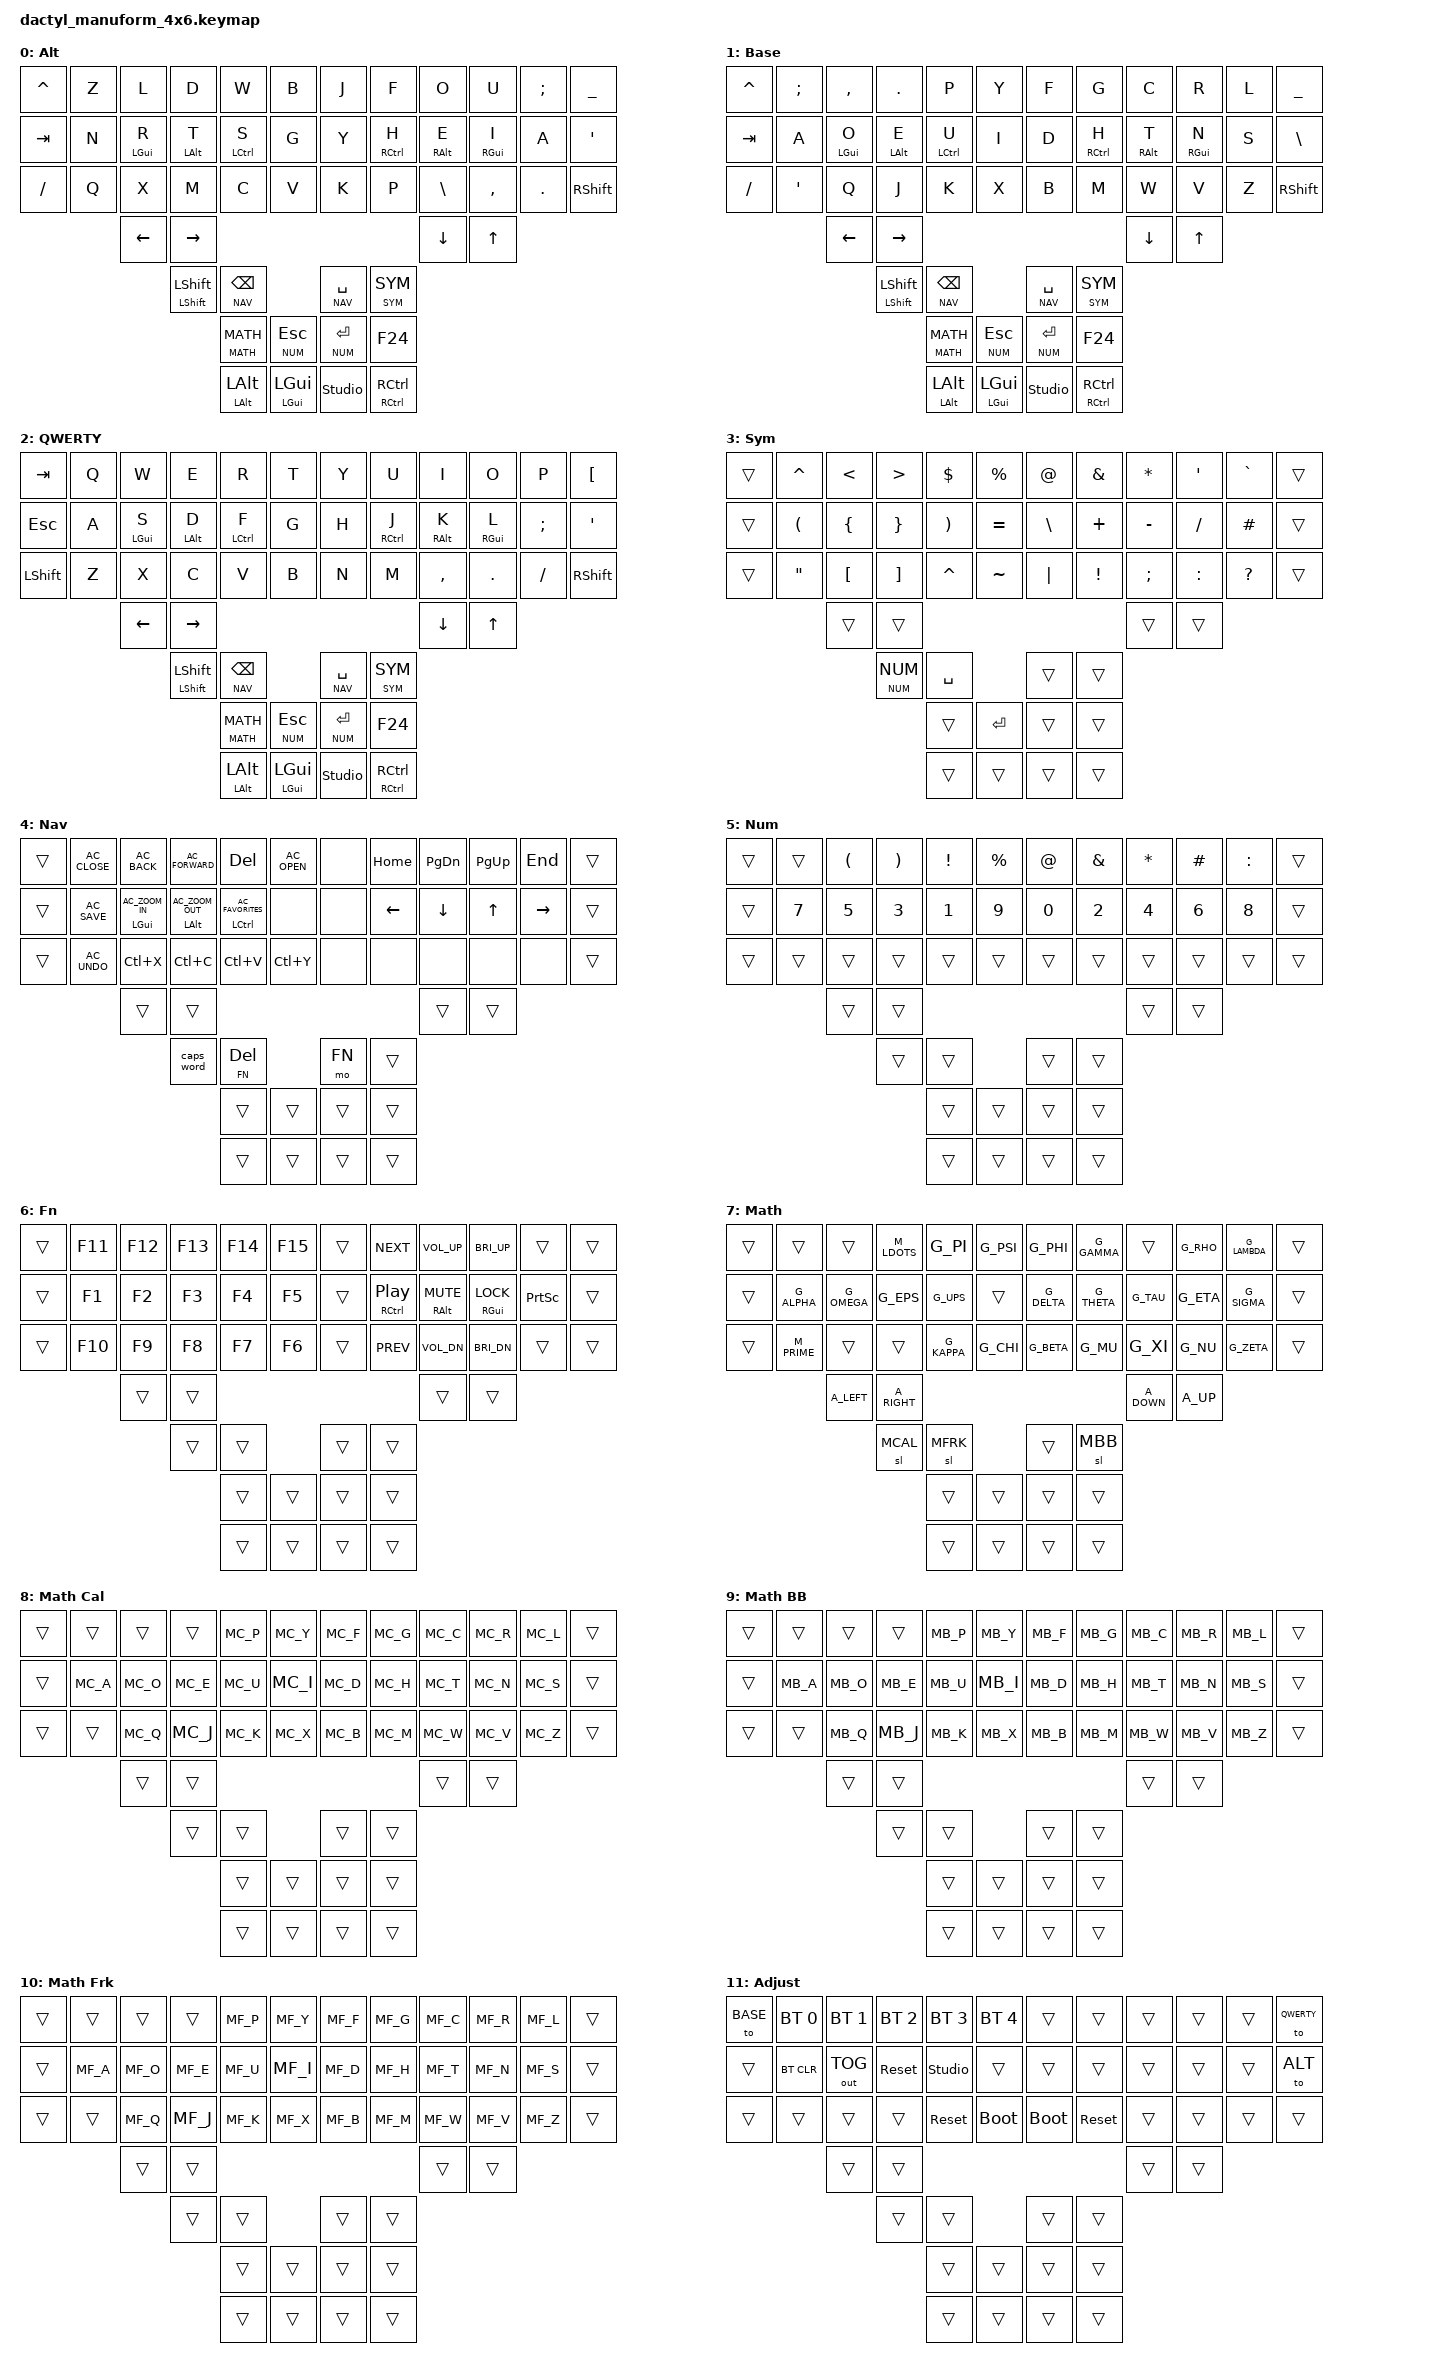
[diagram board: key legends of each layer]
#include <behaviors.dtsi>
#include <dt-bindings/zmk/keys.h>
#include <dt-bindings/zmk/bt.h>
#include <dt-bindings/zmk/outputs.h>
#include <behaviors/unicode.dtsi>   // urob/zmk-unicode: &uc for Unicode input
#include "math_symbols.h"           // G_* / M_* / S_* / A_* / R_* / B_* macros
#include "math_calligraphic.h"      // MC_A .. MC_Z (𝒜 .. 𝒵)
#include "math_doublestruck.h"      // MB_A .. MB_Z (𝔸 .. ℤ)
#include "math_fraktur.h"           // MF_A .. MF_Z (𝔞 .. ℨ)

// ALT-default keymap (Option B: firmware sends character names directly,
// host OS stays on plain US QWERTY when using this keyboard).
//
// LAYER ORDER IS LOAD-BEARING. Index comes from block-order in keymap{}, and
// the highest active index wins at any position. So the three ALPHABET layers
// must sit at the BOTTOM (0-2): an alphabet is fully opaque across all 52
// positions, so anything stacked above it would be masked. Feature layers go
// above them, ADJUST last of all.
//
//   0 ALT    — DEFAULT alphabet, from cyanophage.github.io/playground.
//              HRMs on ring/middle/index home row (r/t/s left, h/e/i right).
//   1 BASE   — Dvorak-Programmer alphabet. Reached via &to BASE on ADJUST.
//   2 QWERTY — standard QWERTY alphabet. Reached via &to QWERTY on ADJUST.
//   3 SYM    — symbols on top row (Programmer Dvorak style), numbers on row 1
//   4 NAV    — arrows on right home row, home/pgdn/pgup/end directly above,
//              both on index/middle/ring/pinky. DEL on left index row 0.
//   5 NUM    — numpad / number entry. Entered by holding L or R mid-inner
//              thumb (which tap to ESC or ENTER respectively).
//   6 FN     — function / media keys. Chained from NAV: while NAV is held,
//              L top-inner (BSPC pos) taps to DEL / holds to FN;
//              R top-inner (SPACE pos) is momentary FN. Row 1 right carries
//              &hp mod-taps because entering FN pins both thumbs.
//   7 MATH   — Unicode math/Greek symbols via urob/zmk-unicode. Tap-sticky
//              MATH (F23 / L mid-outer) then tap a letter → Greek symbol.
//              Mimics cdlatex ;a → α flow. Unshifted / shifted (via
//              &uc CP1 CP2) matches cdlatex first two symbols per key.
//              Requires IBus-capable Linux input method (UC_MODE_LINUX).
//              Switchable at runtime via &uc UC_SET_*.
//              NOTE: these positions were laid out against the Dvorak BASE
//              alphabet, so with ALT as default the letter mnemonic no
//              longer lines up (α sits on ALT's `n`, etc.). Functional but
//              needs remapping to ALT positions to restore the mnemonic.
//   8 MCAL   — Mathematical Script (\mathcal): 𝒜 .. 𝒵. Access: from MATH,
//              tap L top-outer thumb — arms one-shot MCAL for next letter.
//   9 MBB    — Double-Struck (\mathbb): 𝔸 .. ℤ. Access: from MATH, R top-outer.
//  10 MFRK   — Fraktur (\mathfrak): 𝔞/𝔄 .. 𝔷/ℨ. Access: from MATH, L top-inner.
//              Includes lowercase (Lie algebras) on tap; uppercase on shift.
//              (MCAL/MBB/MFRK inherit MATH's Dvorak-alignment caveat.)
//  11 ADJUST — BT profiles + output toggle + layout switch + &studio_unlock.
//              (tri-layer: SYM+NAV, or R bot-inner thumb via ADJ). ADJUST
//              top-left = &to BASE, top-right = &to QWERTY, row 1 right
//              = &to ALT. Highest index so it wins over everything.
//
// The matrix transform (see the shield .dtsi) has been reordered so bindings
// below are written in PHYSICAL rather than matrix-scan order. Each layer
// has 7 visual lines:
//
//   Rows 0-2   alphabet: 6 keys per half (row-major).
//   ext line   the two per half on the thumb-row wiring that sit under
//              middle/ring finger, NOT on the thumb pod. Placed far apart
//              to reflect that they're on opposite halves under fingers.
//   top thumb  the 2 easy sweep-friendly keys per half (top of thumb pod).
//   mid thumb  the 2 middle keys per half — inner one is sweep-friendly.
//   bot thumb  the 2 further-reach keys per half.
//
// Left thumb pod physical shape (right is mirrored):
//   [top1  top2]           <- RC(3,4) RC(3,5)
//       [mid1 mid2]        <- RC(4,4) RC(4,5)
//       [bot1 bot2]        <- RC(4,2) RC(4,3)

// missing: CARET
// missing: backtick

// These MUST match the block order inside keymap{} — ZMK assigns the index
// from block position, not from these names. Alphabets occupy 0-2 so that
// every feature layer outranks them; see the layer-order note above.
#define ALT    0   // default layer
#define BASE   1
#define QWERTY 2
#define SYM    3
#define NAV    4
#define NUM    5
#define FN     6
#define MATH   7
#define MCAL   8
#define MBB    9
#define MFRK   10
#define ADJUST 11   // Highest index so ADJUST wins over everything when tri-layer fires

// Position groups in the physical-order transform (see .dtsi):
//   alphabet:  0..5  L row 0     6..11 R row 0
//              12..17 L row 1    18..23 R row 1
//              24..29 L row 2    30..35 R row 2
//   thumb region (rows 3-4 in matrix):
//              36 37  ext L (ring, middle)     38 39  ext R (middle, ring)
//              40 41  top L thumb              42 43  top R thumb
//              44 45  mid L thumb              46 47  mid R thumb
//              48 49  bot L thumb              50 51  bot R thumb
#define KEYS_L    0  1  2  3  4  5 12 13 14 15 16 17 24 25 26 27 28 29
#define KEYS_R    6  7  8  9 10 11 18 19 20 21 22 23 30 31 32 33 34 35
#define THUMBS   36 37 38 39 40 41 42 43 44 45 46 47 48 49 50 51

// NAV layer aliases — short names so bindings fit in the 12-char cell width.
//
// Editor shortcuts (LC(*)):
#define X_UNDO   &kp LC(Z)
#define X_CUT    &kp LC(X)
#define X_COPY   &kp LC(C)
#define X_PASTE  &kp LC(V)
#define X_REDO   &kp LC(Y)

// R bot inner thumb. NOT ADJUST-entry — ZMK's conditional_layers
// deactivates its then-layer whenever if-layers aren't all active,
// which fights any direct &mo/&to ADJUST from here. ADJUST is entered
// via the SYM+NAV tri-layer instead. This slot is &studio_unlock so
// Studio can be unlocked without first entering ADJUST.
#define ADJ      &studio_unlock

// Sticky-hybrid modifier fills for dactyl bot thumbs — tap = one-shot mod,
// hold = held mod. Enables same-hand mod combos that HRM's positional
// constraint blocks (e.g. Ctrl+D on left hand via RCTL held on right thumb).
#define SALT     &sh LALT LALT
#define SGUI     &sh LGUI LGUI
#define SCTL     &sh RCTL RCTL

// MATH layer entry — sticky-hybrid on F23. Tap = one-shot MATH (mimics
// cdlatex ;letter flow); hold = momentary MATH.
#define MTH      &slh MATH MATH

// Default Unicode input system — Linux IBus. Switch at runtime via
// bindings like &uc UC_SET_MACOS or &uc UC_SET_WIN_COMPOSE if needed.
&uc {
    default-mode = <UC_MODE_LINUX>;
};

/ {
    conditional_layers {
        compatible = "zmk,conditional-layers";
        tri_layer {
            if-layers = <SYM NAV>;
            then-layer = <ADJUST>;
        };
    };

    behaviors {
        // Tap-preferred hold-tap for home-row mods. Tap always wins unless
        // held past tapping-term-ms with an interrupting keypress at an
        // allowed (opposite-hand or thumb) position.
        //   require-prior-idle-ms: suppress hold if any key was pressed in
        //                          the last 125ms — kills typing-burst misfires.
        //   quick-tap-ms: tap-then-hold within 175ms auto-repeats the tap
        //                 keycode (useful for hjkl in vim).
        // Split into left/right variants so each side allows only the
        // opposite hand (+ thumbs) as valid interrupters.
        tpl: tap_preferred_left {
            compatible = "zmk,behavior-hold-tap";
            display-name = "HRM (L)";
            #binding-cells = <2>;
            flavor = "tap-preferred";
            tapping-term-ms = <200>;
            require-prior-idle-ms = <125>;
            quick-tap-ms = <175>;
            hold-trigger-key-positions = <KEYS_R THUMBS>;
            bindings = <&kp>, <&kp>;
        };

        tpr: tap_preferred_right {
            compatible = "zmk,behavior-hold-tap";
            display-name = "HRM (R)";
            #binding-cells = <2>;
            flavor = "tap-preferred";
            tapping-term-ms = <200>;
            require-prior-idle-ms = <125>;
            quick-tap-ms = <175>;
            hold-trigger-key-positions = <KEYS_L THUMBS>;
            bindings = <&kp>, <&kp>;
        };

        // Sticky-hybrid modifier. Tap = one-shot mod (next key is modified,
        // then the mod goes away). Hold = normal held mod. Hold-preferred
        // so fast Shift+letter rollovers register as held shift.
        //   Usage: &sh LSHFT LSHFT
        sh: sticky_hold_mod {
            compatible = "zmk,behavior-hold-tap";
            display-name = "Sticky/Hold";
            #binding-cells = <2>;
            flavor = "hold-preferred";
            tapping-term-ms = <200>;
            quick-tap-ms = <175>;
            bindings = <&kp>, <&sk>;
        };

        // Sticky-hybrid layer. Tap = one-shot layer (next key comes from
        // that layer, then base returns). Hold = momentary layer.
        //   Usage: &slh SYM SYM
        slh: sticky_hold_layer {
            compatible = "zmk,behavior-hold-tap";
            display-name = "Sticky Layer";
            #binding-cells = <2>;
            flavor = "hold-preferred";
            tapping-term-ms = <200>;
            bindings = <&mo>, <&sl>;
        };

        // Hold-preferred layer-tap: hold = layer, tap = key. Fires layer on
        // any interrupt OR after tapping-term. Use for thumb keys where the
        // tap is used deliberately (not in fast typing bursts) — e.g. BSPC.
        //   quick-tap-ms: tap-then-hold within 175ms auto-repeats the tap
        //                 keycode (e.g., tap BSPC, then tap-and-hold to
        //                 auto-repeat backspace).
        //   Usage: &lh NAV BSPC
        lh: layer_hold_preferred {
            compatible = "zmk,behavior-hold-tap";
            display-name = "Layer/Tap (H)";
            #binding-cells = <2>;
            flavor = "hold-preferred";
            tapping-term-ms = <200>;
            quick-tap-ms = <175>;
            bindings = <&mo>, <&kp>;
        };

        // Tap-preferred layer-tap: hold = layer, tap = key. Interrupts do
        // NOT trigger hold — only holding past tapping-term does. Safer for
        // fast-typed keys like SPACE.
        //   Usage: &ltp NAV SPACE
        ltp: layer_tap_preferred {
            compatible = "zmk,behavior-hold-tap";
            display-name = "Layer/Tap (T)";
            #binding-cells = <2>;
            flavor = "tap-preferred";
            tapping-term-ms = <300>;
            require-prior-idle-ms = <125>;
            bindings = <&mo>, <&kp>;
        };

        // Hold-preferred mod-tap for the NAV-layer home-row HRMs. Any
        // interrupting keypress triggers the mod immediately (so mod+arrow
        // combos work without waiting for tapping-term). Quick tap alone
        // fires the tap keycode.
        //   Usage: &hp LGUI C_AC_ZOOM_IN
        hp: hp_hold_preferred_mod {
            compatible = "zmk,behavior-hold-tap";
            display-name = "Mod/Tap";
            #binding-cells = <2>;
            flavor = "hold-preferred";
            tapping-term-ms = <150>;
            bindings = <&kp>, <&kp>;
        };
    };

    keymap {
        compatible = "zmk,keymap";

        // DEFAULT alphabet layout — from cyanophage.github.io/playground
        //   layout=zldwbjfou;\nrtsgyheia'qxmcvkp/,.-^
        // Cols 1-10 are the layout's 3x10 alpha grid; col 0 and col 11 are
        // dactyl-only pinky-outer overrides matching BASE's LaTeX-friendly
        // choices (CARET/TAB/FSLH on left; UNDER/SQT/RSHFT on right).
        // Must be layer 0 and must stay fully opaque (no &trans) — it is the
        // bottom of the stack, so a &trans here resolves to nothing.
        alt_layer {
            display-name = "Alt";
            bindings = <
&kp CARET  &kp Z       &kp L       &kp D       &kp W       &kp B           &kp J       &kp F       &kp O       &kp U       &kp SEMI    &kp UNDER
&kp TAB    &kp N       &tpl LGUI R &tpl LALT T &tpl LCTL S &kp G           &kp Y       &tpr RCTL H &tpr RALT E &tpr RGUI I &kp A       &kp SQT
&kp FSLH   &kp Q       &kp X       &kp M       &kp C       &kp V           &kp K       &kp P       &kp BSLH    &kp COMMA   &kp DOT     &kp RSHFT

                       &kp LEFT    &kp RIGHT                                                       &kp DOWN    &kp UP

                                   &sh LSHFT LSHFT &lh NAV BSPC            &ltp NAV SPACE   &slh SYM SYM
                                               MTH         &lh NUM ESC     &lh NUM RET &kp F24
                                               SALT        SGUI            ADJ         SCTL
            >;
        };

        base_layer {
            display-name = "Base";
            bindings = <
&kp CARET  &kp SEMI    &kp COMMA   &kp DOT     &kp P       &kp Y           &kp F       &kp G       &kp C       &kp R       &kp L       &kp UNDER
&kp TAB    &kp A       &tpl LGUI O &tpl LALT E &tpl LCTL U &kp I           &kp D       &tpr RCTL H &tpr RALT T &tpr RGUI N &kp S       &kp BSLH
&kp FSLH  &kp SQT     &kp Q       &kp J       &kp K       &kp X           &kp B       &kp M       &kp W       &kp V       &kp Z       &kp RSHFT

                       &kp LEFT    &kp RIGHT                                                       &kp DOWN    &kp UP

                                   &sh LSHFT LSHFT &lh NAV BSPC            &ltp NAV SPACE   &slh SYM SYM
                                               MTH         &lh NUM ESC     &lh NUM RET &kp F24
                                               SALT        SGUI            ADJ         SCTL
            >;
        };

        // Standard QWERTY. Thumb/extras mirror base so tri-layer to ADJUST still
        // works (hold SYM+NAV, then top-left of ADJUST returns to BASE).
        qwerty_layer {
            display-name = "QWERTY";
            bindings = <
&kp TAB    &kp Q       &kp W       &kp E       &kp R       &kp T           &kp Y       &kp U       &kp I       &kp O       &kp P       &kp LBKT
&kp ESC    &kp A       &tpl LGUI S &tpl LALT D &tpl LCTL F &kp G           &kp H       &tpr RCTL J &tpr RALT K &tpr RGUI L &kp SEMI    &kp SQT
&kp LSHFT  &kp Z       &kp X       &kp C       &kp V       &kp B           &kp N       &kp M       &kp COMMA   &kp DOT     &kp FSLH    &kp RSHFT

                       &kp LEFT    &kp RIGHT                                                       &kp DOWN    &kp UP

                                   &sh LSHFT LSHFT &lh NAV BSPC        &ltp NAV SPACE   &slh SYM SYM
                                               MTH         &lh NUM ESC     &lh NUM RET &kp F24
                                               SALT        SGUI            ADJ         SCTL
            >;
        };

        sym_layer {
            display-name = "Sym";
            bindings = <
&trans   &kp CARET   &kp LT      &kp GT      &kp DLLR    &kp PRCNT       &kp AT      &kp AMPS    &kp STAR    &kp SQT     &kp GRAVE   &trans
&trans   &kp LPAR    &kp LBRC    &kp RBRC    &kp RPAR    &kp EQUAL       &kp BSLH    &kp PLUS    &kp MINUS   &kp FSLH    &kp HASH    &trans      
&trans   &kp DQT     &kp LBKT    &kp RBKT    &kp CARET   &kp TILDE       &kp PIPE    &kp EXCL    &kp SEMI    &kp COLON   &kp QMARK   &trans

                       &trans      &trans                                                          &trans      &trans

                                   &slh NUM NUM    &kp SPACE           &trans          &trans
                                               &trans      &kp ENTER       &trans      &trans
                                               &trans      &trans          &trans      &trans
            >;
        };

        // VIM_NAV layer, adapted from Selenium's HRM vim variant:
        //   left hand  = editor / app-control shortcuts. Row 0: browser back/
        //                fwd + ctl-w. Row 1: SAVE + ZOOM_IN/OUT + UNDO on the
        //                HRM positions (LGUI/LALT/LCTL still available on
        //                hold via &hp — arrow + mod works cross-hand).
        //                Row 2: undo/cut/copy/paste/redo via LC(*).
        //   right hand = arrows on home row and HOME/PG_DN/PG_UP/END directly
        //                above, both on index/middle/ring/pinky (pos 19-22 and
        //                7-10) so they sit under the resting fingers rather
        //                than one column inward. The inner stretch column
        //                (pos 6/18) is left free. DEL moved to left index row 0
        //                (pos 4); the browser cluster shifted one column out to
        //                the free pinky slot to make room.
        //                Row 2 reserved for mouse-scroll if you later enable
        //                ZMK pointing (currently &none).
        //   thumbs     = caps_word, chain into FN (see behavior comments).
        nav_layer {
            display-name = "Nav";
            bindings = <
&trans     &kp C_AC_CLOSE &kp C_AC_BACK   &kp C_AC_FORWARD &kp DEL             &kp C_AC_OPEN            &none   &kp HOME    &kp PG_DN   &kp PG_UP   &kp END     &trans
&trans     &kp C_AC_SAVE  &hp LGUI C_AC_ZOOM_IN  &hp LALT C_AC_ZOOM_OUT  &hp LCTL C_AC_FAVORITES   &none    &none   &kp LEFT    &kp DOWN    &kp UP      &kp RIGHT   &trans
&trans     &kp C_AC_UNDO  X_CUT       X_COPY      X_PASTE     X_REDO                   &none       &none       &none       &none       &none       &trans

                       &trans      &trans                                                          &trans      &trans

                                   &caps_word      &lh FN DEL          &mo FN          &trans
                                               &trans      &trans          &trans      &trans
                                               &trans      &trans          &trans      &trans
            >;
        };

        // NUM layer — entered by holding L or R mid-inner thumb.
        //   COLON on pos 10 (right pinky row 0, directly above N8) so IP
        //   addresses / ports / timestamps are typeable without leaving the
        //   layer. A real &kp COLON, not shift+SEMI — the thumb holding NUM
        //   makes the shift thumb awkward to reach.
        //   Row 2 is fully &trans — everything it used to bind is already
        //   reachable from the alphabet underneath, so don't duplicate it:
        //     DOT   — pos 34, from ALT's lower right pinky
        //     CARET — pos 0,  from BASE/ALT outer left pinky row 0
        //     UNDER — pos 11, from BASE/ALT outer right pinky row 0
        //   All three are layout-dependent: on BASE pos 34 is Z, and on
        //   QWERTY pos 0/11 are TAB/LBKT rather than CARET/UNDER.
        num_layer {
            display-name = "Num";
            bindings = <
&trans     &trans      &kp LPAR    &kp RPAR    &kp EXCL    &kp PRCNT       &kp AT      &kp AMPS    &kp STAR    &kp HASH    &kp COLON   &trans
&trans     &kp N7      &kp N5      &kp N3      &kp N1      &kp N9          &kp N0      &kp N2      &kp N4      &kp N6      &kp N8      &trans
&trans     &trans      &trans      &trans      &trans      &trans          &trans      &trans      &trans      &trans      &trans      &trans

                       &trans      &trans                                                          &trans      &trans

                                   &trans          &trans              &trans          &trans
                                               &trans      &trans          &trans      &trans
                                               &trans      &trans          &trans      &trans
            >;
        };

        // FN layer — chained from NAV: while NAV is held, tap DEL or hold FN
        // on L top-inner, or momentary FN on R top-inner.
        //
        // Row 1 right = &hp mod-taps: tap = media key, hold = modifier, on
        // the same fingers BASE puts RCTL/RALT/RGUI. Needed because entering
        // FN pins both thumbs (NAV on pos 41 + FN on pos 42), so the bot-row
        // sticky mods are physically unreachable, and FN's own bindings
        // shadow the home-row HRMs. All F-keys are left-hand, so mod+Fn is
        // cross-hand. &hp (not &tpr): no require-prior-idle-ms gate to eat
        // the hold right after the thumb chord, and hold-preferred fires the
        // mod on interrupt instead of waiting out the tapping term.
        fn_layer {
            display-name = "Fn";
            bindings = <
&trans     &kp F11     &kp F12     &kp F13     &kp F14     &kp F15         &trans      &kp C_NEXT       &kp C_VOL_UP     &kp C_BRI_UP      &trans      &trans
&trans     &kp F1      &kp F2      &kp F3      &kp F4      &kp F5          &trans      &hp RCTL C_PLAY_PAUSE &hp RALT C_MUTE &hp RGUI K_LOCK &kp PRINTSCREEN &trans
&trans     &kp F10     &kp F9      &kp F8      &kp F7      &kp F6          &trans      &kp C_PREV       &kp C_VOL_DN     &kp C_BRI_DN      &trans      &trans

                       &trans      &trans                                                          &trans      &trans

                                   &trans          &trans              &trans          &trans
                                               &trans      &trans          &trans      &trans
                                               &trans      &trans          &trans      &trans
            >;
        };

        // MATH layer — Unicode Greek/math symbols mapped to Dvorak letter
        // positions per user's cdlatex-math-symbol-alist. Entered via
        // sticky-hybrid MATH on L mid-outer thumb (was F23).
        //   Unshifted / shifted variants (via &uc CP1 CP2) match cdlatex
        //   first two entries per key.
        //   MATH position → cdlatex trigger correspondence (Dvorak):
        //     a → α    d → δ    e → ε    g → γ    l → λ    o → ω    p → π
        //     s → σ    t → τ    u → υ    r → ρ    m → μ    h → θ    n → η
        //     v → ν    k → κ    b → β    z → ζ    x → χ    y → ψ    f → φ
        //     w → ξ    . → …    ' → ′  (q free, ∨ dropped)
        math_layer {
            display-name = "Math";
            bindings = <
&trans     &trans      &trans      M_LDOTS     G_PI        G_PSI           G_PHI       G_GAMMA     &trans      G_RHO       G_LAMBDA    &trans
&trans     G_ALPHA     G_OMEGA     G_EPS       G_UPS       &trans          G_DELTA     G_THETA     G_TAU       G_ETA       G_SIGMA     &trans
&trans     M_PRIME     &trans      &trans      G_KAPPA     G_CHI           G_BETA      G_MU        G_XI        G_NU        G_ZETA      &trans

                       A_LEFT      A_RIGHT                                                         A_DOWN      A_UP

                                   &sl MCAL    &sl MFRK             &trans          &sl MBB
                                               &trans      &trans          &trans      &trans
                                               &trans      &trans          &trans      &trans
            >;
        };

        // MCAL — Mathematical Script (\mathcal). Uppercase-only.
        // Positions aligned to Dvorak base: A → 𝒜, B → ℬ, ..., Z → 𝒵.
        mcal_layer {
            display-name = "Math Cal";
            bindings = <
&trans     &trans      &trans      &trans      MC_P        MC_Y            MC_F        MC_G        MC_C        MC_R        MC_L        &trans
&trans     MC_A        MC_O        MC_E        MC_U        MC_I            MC_D        MC_H        MC_T        MC_N        MC_S        &trans
&trans     &trans      MC_Q        MC_J        MC_K        MC_X            MC_B        MC_M        MC_W        MC_V        MC_Z        &trans

                       &trans      &trans                                                          &trans      &trans

                                   &trans          &trans              &trans          &trans
                                               &trans      &trans          &trans      &trans
                                               &trans      &trans          &trans      &trans
            >;
        };

        // MBB — Double-Struck (\mathbb). Uppercase-only.
        mbb_layer {
            display-name = "Math BB";
            bindings = <
&trans     &trans      &trans      &trans      MB_P        MB_Y            MB_F        MB_G        MB_C        MB_R        MB_L        &trans
&trans     MB_A        MB_O        MB_E        MB_U        MB_I            MB_D        MB_H        MB_T        MB_N        MB_S        &trans
&trans     &trans      MB_Q        MB_J        MB_K        MB_X            MB_B        MB_M        MB_W        MB_V        MB_Z        &trans

                       &trans      &trans                                                          &trans      &trans

                                   &trans          &trans              &trans          &trans
                                               &trans      &trans          &trans      &trans
                                               &trans      &trans          &trans      &trans
            >;
        };

        // MFRK — Fraktur (\mathfrak). Tap = lowercase (useful for Lie
        // algebras: 𝔤 𝔥 etc.); shift-tap = uppercase (𝔄 𝔅 ...).
        mfrk_layer {
            display-name = "Math Frk";
            bindings = <
&trans     &trans      &trans      &trans      MF_P        MF_Y            MF_F        MF_G        MF_C        MF_R        MF_L        &trans
&trans     MF_A        MF_O        MF_E        MF_U        MF_I            MF_D        MF_H        MF_T        MF_N        MF_S        &trans
&trans     &trans      MF_Q        MF_J        MF_K        MF_X            MF_B        MF_M        MF_W        MF_V        MF_Z        &trans

                       &trans      &trans                                                          &trans      &trans

                                   &trans          &trans              &trans          &trans
                                               &trans      &trans          &trans      &trans
                                               &trans      &trans          &trans      &trans
            >;
        };

        // ADJUST last so it wins over the alphabet layers (QWERTY/ALT) and
        // math layers when tri-layer (SYM+NAV) or ADJ thumb activates it.
        adjust_layer {
            display-name = "Adjust";
            bindings = <
&to BASE   &bt BT_SEL 0 &bt BT_SEL 1 &bt BT_SEL 2 &bt BT_SEL 3 &bt BT_SEL 4  &trans      &trans      &trans      &trans      &trans    &to QWERTY
&trans     &bt BT_CLR   &out OUT_TOG &sys_reset &studio_unlock &trans      &trans      &trans      &trans      &trans      &trans      &to ALT
&trans     &trans      &trans      &trans      &sys_reset  &bootloader     &bootloader &sys_reset  &trans      &trans      &trans      &trans

                       &trans      &trans                                                          &trans      &trans

                                   &trans          &trans              &trans          &trans
                                               &trans      &trans          &trans      &trans
                                               &trans      &trans          &trans      &trans
            >;
        };
    };
};
